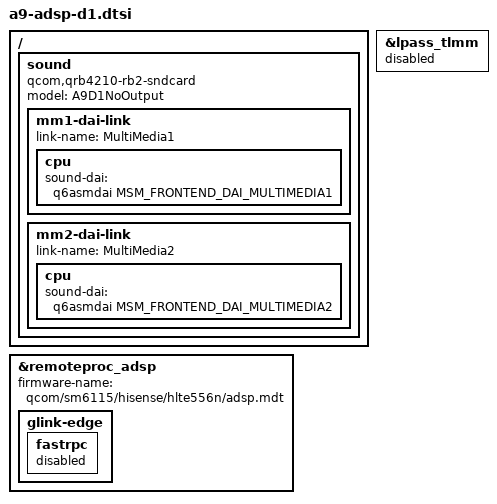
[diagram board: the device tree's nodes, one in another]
// SPDX-License-Identifier: (GPL-2.0+ OR BSD-3-Clause)
/*
 * Hisense A9 (HLTE556N) -- ADSP stage D1: sound card enumerates, NO output
 * (runs/adsp-plan.md, runs/adsp-d1-prep.md). #included LAST, after the integ-1
 * board DT (sm6115-hisense-hlte556n-android-gpu-thermal.dts), by
 * scripts/mainline/adsp/build-d1-dtb.sh. Wired into no default build.
 *
 * Delta against integ-1 (check-d1-dt.py enforces it exactly):
 *  - remoteproc@a400000: status okay + firmware-name (same as D0).
 *  - its glink-edge FastRPC: disabled (as D0; compute-cb SMMU stream IDs stay
 *    unclaimed, and there is no consumer in D1).
 *  - LPASS LPI pinctrl: disabled (as D0). It needs the q6afe clock provider and
 *    would touch LPASS MMIO/pins; D1 declares NO pinctrl, no pin function.
 *  - the glink-edge APR node is NOT touched: the upstream sm6115.dtsi tree
 *    (apr-v2, channel "apr_audio_svc", domain ADSP, services q6core@3 q6afe@4
 *    q6asm@7 q6adm@8, all with protection domain avs/audio ->
 *    msm/adsp/audio_pd) is the intended D1 payload.
 *  - one new /sound node, compatible "qcom,qrb4210-rb2-sndcard" (an existing
 *    sm8250.c match entry, driver_name "sm4250"; reused only because it is the
 *    SM4250/SM6115-family compatible already in the tree; no kernel patch).
 *
 * The card contains ONLY two front-end links (MultiMedia1/2, q6asm-dai). A
 * link with no codec/platform child gets the dummy codec + dynamic (DPCM)
 * front end from sound/soc/qcom/common.c. There is NO back-end link, so no
 * AFE port, MI2S/LPAI/SoundWire/WCD/WSA/ES9218/aw87xxx DAI exists, no codec or
 * amplifier node is referenced, no GPIO/regulator/pinctrl/clock property is
 * present, and no audio-routing/widget/jack is defined. Opening a PCM would
 * route to nothing; the D1 harness never opens one.
 *
 * Measured vs inferred: that the stock ADSP firmware's audio PD comes up for
 * this tree (PDR "avs/audio" UP, then the four APR services) is NOT measured:
 * the D0 run had APR disabled. The D1 harness waits a bounded time and fails
 * closed. The model string is chosen to equal the ALSA card id (alphanumeric).
 */
#include <dt-bindings/sound/qcom,q6asm.h>

&remoteproc_adsp {
	firmware-name = "qcom/sm6115/hisense/hlte556n/adsp.mdt";
	status = "okay";

	glink-edge {
		fastrpc {
			status = "disabled";
		};
	};
};

&lpass_tlmm {
	status = "disabled";
};

/ {
	sound {
		compatible = "qcom,qrb4210-rb2-sndcard";
		model = "A9D1NoOutput";

		mm1-dai-link {
			link-name = "MultiMedia1";

			cpu {
				sound-dai = <&q6asmdai MSM_FRONTEND_DAI_MULTIMEDIA1>;
			};
		};

		mm2-dai-link {
			link-name = "MultiMedia2";

			cpu {
				sound-dai = <&q6asmdai MSM_FRONTEND_DAI_MULTIMEDIA2>;
			};
		};
	};
};
